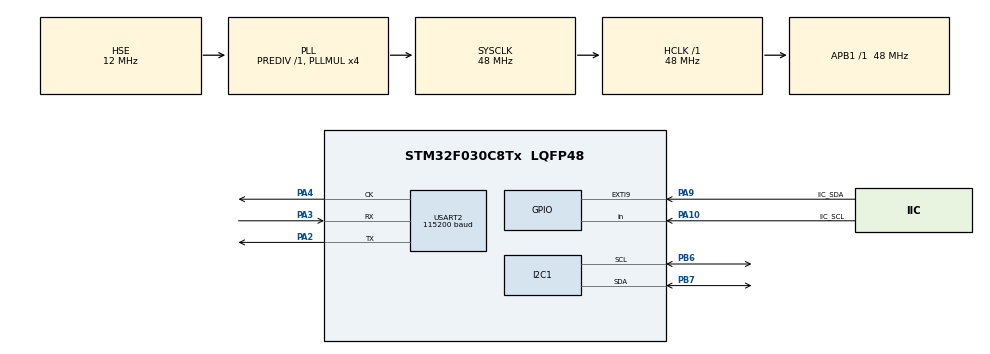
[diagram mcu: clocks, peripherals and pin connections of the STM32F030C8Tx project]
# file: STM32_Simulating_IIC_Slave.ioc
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Mcu.Family=STM32F0
Mcu.Name=STM32F030C8Tx
Mcu.Package=LQFP48
NVIC.EXTI4_15_IRQn=true\:0\:0\:false\:false\:true\:true
PA10.GPIO_Label=IIC_SCL
PA10.GPIO_PuPd=GPIO_NOPULL
PA10.Signal=GPIO_Input
PA13.Mode=Serial_Wire
PA13.Signal=SYS_SWDIO
PA14.Mode=Serial_Wire
PA14.Signal=SYS_SWCLK
PA2.Mode=Synchronous
PA2.Signal=USART2_TX
PA3.Mode=Synchronous
PA3.Signal=USART2_RX
PA4.Mode=Synchronous
PA4.Signal=USART2_CK
PA9.GPIO_Label=IIC_SDA
PA9.GPIO_ModeDefaultEXTI=GPIO_MODE_IT_FALLING
PA9.Signal=GPXTI9
PB6.Mode=I2C
PB6.Signal=I2C1_SCL
PB7.Mode=I2C
PB7.Signal=I2C1_SDA
PF0-OSC_IN.Mode=HSE-External-Oscillator
PF0-OSC_IN.Signal=RCC_OSC_IN
PF1-OSC_OUT.Mode=HSE-External-Oscillator
PF1-OSC_OUT.Signal=RCC_OSC_OUT
ProjectManager.HeapSize=0x200
ProjectManager.StackSize=0x400
ProjectManager.TargetToolchain=MDK-ARM V5
RCC.AHBFreq_Value=48000000
RCC.APB1Freq_Value=48000000
RCC.APB1TimFreq_Value=48000000
RCC.HCLKFreq_Value=48000000
RCC.HSE_VALUE=12000000
RCC.PLLMUL=RCC_PLL_MUL4
RCC.PLLSourceVirtual=RCC_PLLSOURCE_HSE
RCC.SYSCLKFreq_VALUE=48000000
RCC.SYSCLKSource=RCC_SYSCLKSOURCE_PLLCLK
USART2.BaudRate=115200
USART2.VirtualMode-Synchronous=VM_SYNC
board=STM32_Simulating_IIC_Slave

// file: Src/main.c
/**
  ******************************************************************************
  * File Name          : main.c
  * Description        : Main program body
  ******************************************************************************
  ** This notice applies to any and all portions of this file
  * that are not between comment pairs USER CODE BEGIN and
  * USER CODE END. Other portions of this file, whether
  * inserted by the user or by software development tools
  * are owned by their respective copyright owners.
  *
  * COPYRIGHT(c) 2018 STMicroelectronics
  *
  * Redistribution and use in source and binary forms, with or without modification,
  * are permitted provided that the following conditions are met:
  *   1. Redistributions of source code must retain the above copyright notice,
  *      this list of conditions and the following disclaimer.
  *   2. Redistributions in binary form must reproduce the above copyright notice,
  *      this list of conditions and the following disclaimer in the documentation
  *      and/or other materials provided with the distribution.
  *   3. Neither the name of STMicroelectronics nor the names of its contributors
  *      may be used to endorse or promote products derived from this software
  *      without specific prior written permission.
  *
  * THIS SOFTWARE IS PROVIDED BY THE COPYRIGHT HOLDERS AND CONTRIBUTORS "AS IS"
  * AND ANY EXPRESS OR IMPLIED WARRANTIES, INCLUDING, BUT NOT LIMITED TO, THE
  * IMPLIED WARRANTIES OF MERCHANTABILITY AND FITNESS FOR A PARTICULAR PURPOSE ARE
  * DISCLAIMED. IN NO EVENT SHALL THE COPYRIGHT HOLDER OR CONTRIBUTORS BE LIABLE
  * FOR ANY DIRECT, INDIRECT, INCIDENTAL, SPECIAL, EXEMPLARY, OR CONSEQUENTIAL
  * DAMAGES (INCLUDING, BUT NOT LIMITED TO, PROCUREMENT OF SUBSTITUTE GOODS OR
  * SERVICES; LOSS OF USE, DATA, OR PROFITS; OR BUSINESS INTERRUPTION) HOWEVER
  * CAUSED AND ON ANY THEORY OF LIABILITY, WHETHER IN CONTRACT, STRICT LIABILITY,
  * OR TORT (INCLUDING NEGLIGENCE OR OTHERWISE) ARISING IN ANY WAY OUT OF THE USE
  * OF THIS SOFTWARE, EVEN IF ADVISED OF THE POSSIBILITY OF SUCH DAMAGE.
  *
  ******************************************************************************
  */

#include "main.h"
#include "stm32f0xx_hal.h"
#include "i2c.h"
#include "usart.h"
#include "gpio.h"

/* USER CODE BEGIN Includes */
#include "Simulating_IIC.h"
/* USER CODE END Includes */

/* USER CODE BEGIN PV */
/* Private variables ---------------------------------------------------------*/

/* USER CODE END PV */

void SystemClock_Config(void);

/* USER CODE BEGIN PFP */
/* Private function prototypes -----------------------------------------------*/

/* USER CODE END PFP */

int main(void)
{

  /* MCU Configuration----------------------------------------------------------*/

  /* Reset of all peripherals, Initializes the Flash interface and the Systick. */
  HAL_Init();

  /* Configure the system clock */
  SystemClock_Config();

  /* Initialize all configured peripherals */
  MX_GPIO_Init();
  MX_I2C1_Init();
  MX_USART2_Init();

  /* USER CODE BEGIN 2 */
  printf("Start\r\n");
//  HAL_GPIO_WritePin(IIC_SDA_GPIO_Port, IIC_SDA_Pin, GPIO_PIN_SET);
  /* USER CODE END 2 */

  /* Infinite loop */
  while (1)
  {

  }

}

/** System Clock Configuration
*/
void SystemClock_Config(void)
{

  RCC_OscInitTypeDef RCC_OscInitStruct;
  RCC_ClkInitTypeDef RCC_ClkInitStruct;
  RCC_PeriphCLKInitTypeDef PeriphClkInit;

    /**Initializes the CPU, AHB and APB busses clocks
    */
  RCC_OscInitStruct.OscillatorType = RCC_OSCILLATORTYPE_HSI|RCC_OSCILLATORTYPE_HSE;
  RCC_OscInitStruct.HSEState = RCC_HSE_ON;
  RCC_OscInitStruct.HSIState = RCC_HSI_ON;
  RCC_OscInitStruct.HSICalibrationValue = 16;
  RCC_OscInitStruct.PLL.PLLState = RCC_PLL_ON;
  RCC_OscInitStruct.PLL.PLLSource = RCC_PLLSOURCE_HSE;
  RCC_OscInitStruct.PLL.PLLMUL = RCC_PLL_MUL4;
  RCC_OscInitStruct.PLL.PREDIV = RCC_PREDIV_DIV1;
  if (HAL_RCC_OscConfig(&RCC_OscInitStruct) != HAL_OK)
  {
    _Error_Handler(__FILE__, __LINE__);
  }

    /**Initializes the CPU, AHB and APB busses clocks
    */
  RCC_ClkInitStruct.ClockType = RCC_CLOCKTYPE_HCLK|RCC_CLOCKTYPE_SYSCLK
                              |RCC_CLOCKTYPE_PCLK1;
  RCC_ClkInitStruct.SYSCLKSource = RCC_SYSCLKSOURCE_PLLCLK;
  RCC_ClkInitStruct.AHBCLKDivider = RCC_SYSCLK_DIV1;
  RCC_ClkInitStruct.APB1CLKDivider = RCC_HCLK_DIV1;

  if (HAL_RCC_ClockConfig(&RCC_ClkInitStruct, FLASH_LATENCY_1) != HAL_OK)
  {
    _Error_Handler(__FILE__, __LINE__);
  }

  PeriphClkInit.PeriphClockSelection = RCC_PERIPHCLK_I2C1;
  PeriphClkInit.I2c1ClockSelection = RCC_I2C1CLKSOURCE_HSI;
  if (HAL_RCCEx_PeriphCLKConfig(&PeriphClkInit) != HAL_OK)
  {
    _Error_Handler(__FILE__, __LINE__);
  }

    /**Configure the Systick interrupt time
    */
  HAL_SYSTICK_Config(HAL_RCC_GetHCLKFreq()/1000);

    /**Configure the Systick
    */
  HAL_SYSTICK_CLKSourceConfig(SYSTICK_CLKSOURCE_HCLK);

  /* SysTick_IRQn interrupt configuration */
  HAL_NVIC_SetPriority(SysTick_IRQn, 0, 0);
}

void _Error_Handler(char * file, int line)
{
  while(1)
  {
  }
}

/************************ (C) COPYRIGHT STMicroelectronics *****END OF FILE****/
